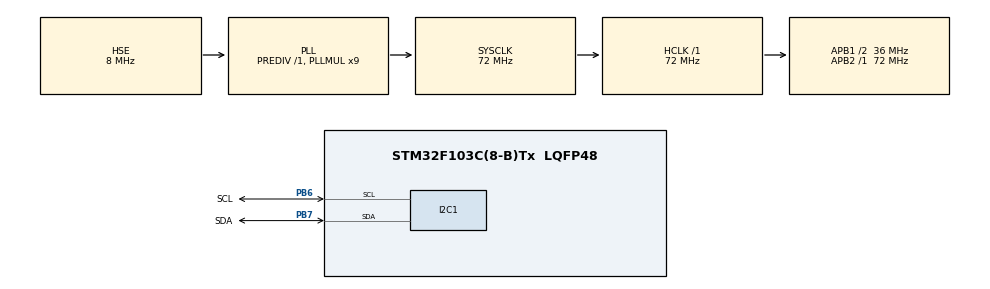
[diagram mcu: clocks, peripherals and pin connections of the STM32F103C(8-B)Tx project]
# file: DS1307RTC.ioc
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I2C1.I2C_Mode=I2C_Standard
Mcu.Family=STM32F1
Mcu.Name=STM32F103C(8-B)Tx
Mcu.Package=LQFP48
NVIC.PriorityGroup=NVIC_PRIORITYGROUP_4
PA13.Mode=Serial_Wire
PA13.Signal=SYS_JTMS-SWDIO
PA14.Mode=Serial_Wire
PA14.Signal=SYS_JTCK-SWCLK
PB6.GPIO_Label=SCL
PB6.Mode=I2C
PB6.Signal=I2C1_SCL
PB7.GPIO_Label=SDA
PB7.Mode=I2C
PB7.Signal=I2C1_SDA
PD0-OSC_IN.Mode=HSE-External-Oscillator
PD0-OSC_IN.Signal=RCC_OSC_IN
PD1-OSC_OUT.Mode=HSE-External-Oscillator
PD1-OSC_OUT.Signal=RCC_OSC_OUT
ProjectManager.HeapSize=0x200
ProjectManager.StackSize=0x400
ProjectManager.TargetToolchain=MDK-ARM V5.32
RCC.AHBFreq_Value=72000000
RCC.APB1CLKDivider=RCC_HCLK_DIV2
RCC.APB1Freq_Value=36000000
RCC.APB1TimFreq_Value=72000000
RCC.APB2Freq_Value=72000000
RCC.APB2TimFreq_Value=72000000
RCC.HCLKFreq_Value=72000000
RCC.PLLMUL=RCC_PLL_MUL9
RCC.PLLSourceVirtual=RCC_PLLSOURCE_HSE
RCC.SYSCLKFreq_VALUE=72000000
RCC.SYSCLKSource=RCC_SYSCLKSOURCE_PLLCLK
RCC.USBFreq_Value=72000000
board=custom

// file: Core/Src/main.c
/* USER CODE BEGIN Header */
/**
  ******************************************************************************
  * @file           : main.c
  * @brief          : Main program body
  ******************************************************************************
  * @attention
  *
  * Copyright (c) 2024 STMicroelectronics.
  * All rights reserved.
  *
  * This software is licensed under terms that can be found in the LICENSE file
  * in the root directory of this software component.
  * If no LICENSE file comes with this software, it is provided AS-IS.
  *
  ******************************************************************************
  */
/* USER CODE END Header */
#include "main.h"

/* USER CODE BEGIN Includes */
uint8_t WriteBuffer[8]={0,0x27,0x59,0x71,0,0x31,0x12,0x99};// RTC starting from 31/12/99, 00, 11:59:27 PM
uint8_t ReadBuffer[7];
uint8_t ModBuffer[7];
uint8_t PointerReset=0;
uint8_t error=0;
/* USER CODE END Includes */

I2C_HandleTypeDef hi2c1;

void SystemClock_Config(void);
static void MX_GPIO_Init(void);
static void MX_I2C1_Init(void);

int main(void)
{

  /* MCU Configuration--------------------------------------------------------*/

  /* Reset of all peripherals, Initializes the Flash interface and the Systick. */
  HAL_Init();

  /* Configure the system clock */
  SystemClock_Config();

  /* Initialize all configured peripherals */
  MX_GPIO_Init();
  MX_I2C1_Init();
  /* USER CODE BEGIN 2 */

if(HAL_I2C_IsDeviceReady(&hi2c1,((0x68)<<1),5,1)==HAL_OK)
{
	HAL_I2C_Master_Transmit(&hi2c1,((0x68)<<1),(uint8_t *)WriteBuffer,8,1);
}
else{
	Error_Handler();
}

  /* USER CODE END 2 */

  /* Infinite loop */
  /* USER CODE BEGIN WHILE */
  while (1)
  {
		if(HAL_I2C_IsDeviceReady(&hi2c1,((0x68)<<1),5,1)==HAL_OK)
			{
					HAL_I2C_Master_Transmit(&hi2c1,((0x68)<<1),&PointerReset,1,1);
			}
		if(HAL_I2C_IsDeviceReady(&hi2c1,((0x68)<<1),5,1)==HAL_OK)
     {
	        HAL_I2C_Master_Receive(&hi2c1,((0x68)<<1),(uint8_t *)ReadBuffer,7,1);
     }
			ModBuffer[0]=(((ReadBuffer[0]&0x70)>>4)*10)+((ReadBuffer[0]&0x0F));//Seconds Data
			ModBuffer[1]=(((ReadBuffer[1]&0x70)>>4)*10)+((ReadBuffer[1]&0x0F));//Minutes Data
			ModBuffer[2]=(((ReadBuffer[2]&0x10)>>4)*10)+((ReadBuffer[2]&0x0F));//Hours Data
			ModBuffer[3]=((ReadBuffer[3]&0x07));                               //Day of the Week Data
			ModBuffer[4]=(((ReadBuffer[4]&0x30)>>4)*10)+((ReadBuffer[4]&0x0F));//Date Data
			ModBuffer[5]=(((ReadBuffer[5]&0x10)>>4)*10)+((ReadBuffer[5]&0x0F));//Month Data
			ModBuffer[6]=(((ReadBuffer[6]&0xF0)>>4)*10)+((ReadBuffer[6]&0x0F));//Year Data

 HAL_Delay(1000);
    /* USER CODE END WHILE */

  }
}

void SystemClock_Config(void)
{
  RCC_OscInitTypeDef RCC_OscInitStruct = {0};
  RCC_ClkInitTypeDef RCC_ClkInitStruct = {0};

  /** Initializes the RCC Oscillators according to the specified parameters
  * in the RCC_OscInitTypeDef structure.
  */
  RCC_OscInitStruct.OscillatorType = RCC_OSCILLATORTYPE_HSE;
  RCC_OscInitStruct.HSEState = RCC_HSE_ON;
  RCC_OscInitStruct.HSEPredivValue = RCC_HSE_PREDIV_DIV1;
  RCC_OscInitStruct.HSIState = RCC_HSI_ON;
  RCC_OscInitStruct.PLL.PLLState = RCC_PLL_ON;
  RCC_OscInitStruct.PLL.PLLSource = RCC_PLLSOURCE_HSE;
  RCC_OscInitStruct.PLL.PLLMUL = RCC_PLL_MUL9;
  if (HAL_RCC_OscConfig(&RCC_OscInitStruct) != HAL_OK)
  {
    Error_Handler();
  }

  /** Initializes the CPU, AHB and APB buses clocks
  */
  RCC_ClkInitStruct.ClockType = RCC_CLOCKTYPE_HCLK|RCC_CLOCKTYPE_SYSCLK
                              |RCC_CLOCKTYPE_PCLK1|RCC_CLOCKTYPE_PCLK2;
  RCC_ClkInitStruct.SYSCLKSource = RCC_SYSCLKSOURCE_PLLCLK;
  RCC_ClkInitStruct.AHBCLKDivider = RCC_SYSCLK_DIV1;
  RCC_ClkInitStruct.APB1CLKDivider = RCC_HCLK_DIV2;
  RCC_ClkInitStruct.APB2CLKDivider = RCC_HCLK_DIV1;

  if (HAL_RCC_ClockConfig(&RCC_ClkInitStruct, FLASH_LATENCY_2) != HAL_OK)
  {
    Error_Handler();
  }
}

static void MX_I2C1_Init(void)
{

  hi2c1.Instance = I2C1;
  hi2c1.Init.ClockSpeed = 100000;
  hi2c1.Init.DutyCycle = I2C_DUTYCYCLE_2;
  hi2c1.Init.OwnAddress1 = 0;
  hi2c1.Init.AddressingMode = I2C_ADDRESSINGMODE_7BIT;
  hi2c1.Init.DualAddressMode = I2C_DUALADDRESS_DISABLE;
  hi2c1.Init.OwnAddress2 = 0;
  hi2c1.Init.GeneralCallMode = I2C_GENERALCALL_DISABLE;
  hi2c1.Init.NoStretchMode = I2C_NOSTRETCH_DISABLE;
  if (HAL_I2C_Init(&hi2c1) != HAL_OK)
  {
    Error_Handler();
  }

}

static void MX_GPIO_Init(void)
{

  /* GPIO Ports Clock Enable */
  __HAL_RCC_GPIOD_CLK_ENABLE();
  __HAL_RCC_GPIOA_CLK_ENABLE();
  __HAL_RCC_GPIOB_CLK_ENABLE();

}

void Error_Handler(void)
{
  /* USER CODE BEGIN Error_Handler_Debug */
	error=1;
  /* User can add his own implementation to report the HAL error return state */
  __disable_irq();
  while (1)
  {
  }
  /* USER CODE END Error_Handler_Debug */
}
